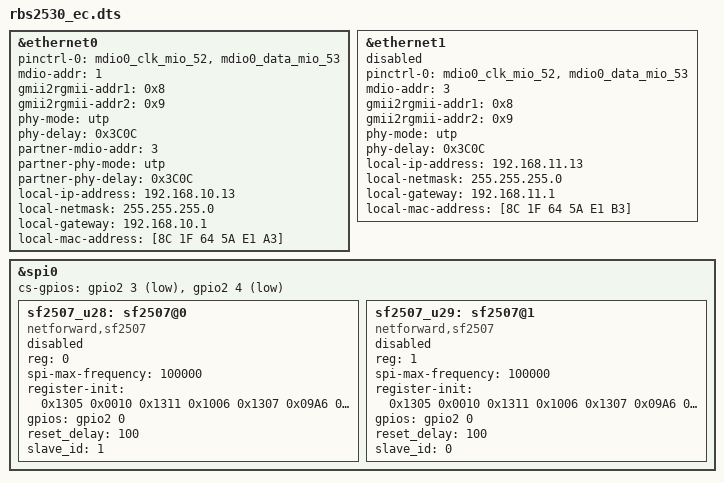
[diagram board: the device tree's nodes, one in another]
/*
 * Copyright (c) 2024 SYSTech Co.
 * SPDX-License-Identifier: Apache-2.0
 */

/dts-v1/;

#include <fmsh/rbs2530.dtsi>
#include <dt-bindings/gpio/gpio.h>


&ethernet0 {
	pinctrl-0 = <&mdio0_clk_mio_52>, <&mdio0_data_mio_53>;
	pinctrl-names = "default";
	mdio-addr = <1>;
	gmii2rgmii-addr1 = <0x8>;
	gmii2rgmii-addr2 = <0x9>;
	phy-mode = "utp";  /* fiber or utp */
	phy-delay = <0x3C0C>;
	partner-mdio-addr = <3>;
	partner-phy-mode = "utp";
	partner-phy-delay = <0x3C0C>;
	local-ip-address = "192.168.10.13";
	local-netmask = "255.255.255.0";
	local-gateway = "192.168.10.1";
	local-mac-address = [8C 1F 64 5A E1 A3];
	status = "okay";
};


&ethernet1 {
	pinctrl-0 = <&mdio0_clk_mio_52>, <&mdio0_data_mio_53>;
	pinctrl-names = "default";
	mdio-addr = <3>;
	gmii2rgmii-addr1 = <0x8>;
	gmii2rgmii-addr2 = <0x9>;
	phy-mode = "utp";  /* fiber or utp */
	phy-delay = <0x3C0C>;
	local-ip-address = "192.168.11.13";
	local-netmask = "255.255.255.0";
	local-gateway = "192.168.11.1";
	local-mac-address = [8C 1F 64 5A E1 B3];
	status = "disabled";
};

&spi0 {
	cs-gpios = <&gpio2 3 GPIO_ACTIVE_LOW>, <&gpio2 4 GPIO_ACTIVE_LOW>;

	sf2507_u28: sf2507@0 {
		compatible = "netforward,sf2507";
		reg = <0>;
		status = "disabled";
		spi-max-frequency = <100000>;
		register-init = <
			0x1305 0x0010
			0x1311 0x1006
			0x1307 0x09A6
			0x3B0C 0x0003
			0x13C3 0x0001
			0x13C4 0x1006
			0x13C5 0x09A6
			0x3B0D 0x0003
			0x3EE0 0x0022
			0x3BE4 0x0003
		>;
		gpios = <&gpio2 0 0>;
		reset_delay = <100>;
		slave_id = <1>;
	};

	sf2507_u29: sf2507@1 {
		compatible = "netforward,sf2507";
		reg = <1>;
		status = "disabled";
		spi-max-frequency = <100000>;
		register-init = <
			0x1305 0x0010
			0x1311 0x1006
			0x1307 0x09A6
			0x3B0C 0x0003
			0x13C3 0x0001
			0x13C4 0x1006
			0x13C5 0x09A6
			0x3B0D 0x0003
			0x3EE0 0x0022
			0x3BE4 0x0003
		>;
		gpios = <&gpio2 0 0>;
		reset_delay = <100>;
		slave_id = <0>;
	};
};
